# DSS_PRM register map
Vendor: Texas Instruments
Peripheral module from a debugger description file (folder TDA2Px).
Registers are 32-bit, access per field, reset 0x0 unless marked. A register's access mark holds for its fields unless they carry their own. Offsets are as the file gives them; lines under a group give offsets from that group; [hi:lo] are bit positions; {n}, {i} and the like mark numbered series; 'fields as' and 'values as' point back to an identical list; <NAME> marks a mode.

## DSS_PRM
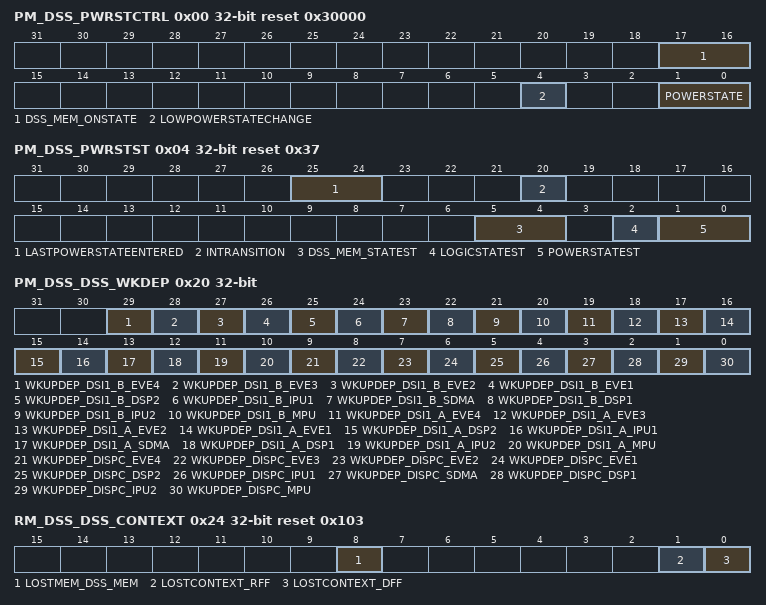
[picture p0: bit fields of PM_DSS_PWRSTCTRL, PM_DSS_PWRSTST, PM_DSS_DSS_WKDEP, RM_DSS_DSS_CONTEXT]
0x00 PM_DSS_PWRSTCTRL reset 0x30000 — This register controls the DSS power state to reach upon a domain sleep transition
  [17:16] DSS_MEM_ONSTATE ro — DSS_MEM state when domain is ON.
    3=MEM_ON (Memory bank is on when the domain is ON.)
  [4] LOWPOWERSTATECHANGE rw — Power state change request when domain has already performed a sleep transition. Allows going into deeper low power state without waking up the power domain.
    0=DIS (Do not request a low power state change.); 1=EN (Request a low power state change. This bit is automatically cleared when the power state is effectively changed or when power state is ON.)
  [1:0] POWERSTATE rw — Power state control
    0=OFF (OFF state); 1=RET (Reserved); 2=INACT (Reserved); 3=ON (ON State)
0x04 PM_DSS_PWRSTST reset 0x37 — This register provides a status on the current DSS power domain state. [warm reset insensitive]
  [25:24] LASTPOWERSTATEENTERED rw — Last low power state entered. Set to 0x3 upon write of the same only. This register is intended for debug purpose only.
    0=OFF (Power domain was previously OFF); 1=RET (Reserved); 2=INACTIVE (Reserved); 3=ON (Power domain was previously ON-ACTIVE)
  [20] INTRANSITION ro — Domain transition status
    0=NO (No on-going transition on power domain); 1=ONGOING (Power domain transition is in progress.)
  [5:4] DSS_MEM_STATEST ro — DSS_MEM state status
    0=MEM_OFF (Memory is OFF); 3=MEM_ON (Memory is ON)
  [2] LOGICSTATEST ro — Logic state status
    0=OFF (Reserved); 1=ON (Logic in domain is ON)
  [1:0] POWERSTATEST ro — Current power state status
    0=OFF (Power domain is OFF); 1=RET (Reserved); 2=INACTIVE (Reserved); 3=ON (Power domain is ON-ACTIVE)
0x20 PM_DSS_DSS_WKDEP — This register controls wakeup dependency based on DSS service requests.
  [29] WKUPDEP_DSI1_B_EVE4 rw — Wakeup dependency from DSS module (SWakeup signal) towards EVE4 + L3_MAIN1 + L4PER1 + L4PER2 + L4PER3 domainsEVE4 is not supported in this family of devices.
    0=DISABLED (Dependency is disabled); 1=ENABLED (Dependency is enabled)
  [28] WKUPDEP_DSI1_B_EVE3 rw — Wakeup dependency from DSS module (SWakeup signal) towards EVE3 + L3_MAIN1 + L4PER1 + L4PER2 + L4PER3 domainsEVE3 is not supported in this family of devices.
    values as WKUPDEP_DSI1_B_EVE4
  [27] WKUPDEP_DSI1_B_EVE2 rw — Wakeup dependency from DSS module (SWakeup signal) towards EVE2 + L3_MAIN1 + L4PER1 + L4PER2 + L4PER3 domains
    values as WKUPDEP_DSI1_B_EVE4
  [26] WKUPDEP_DSI1_B_EVE1 rw — Wakeup dependency from DSS module (SWakeup signal) towards EVE1 + L3_MAIN1 + L4PER1 + L4PER2 + L4PER3 domains
    values as WKUPDEP_DSI1_B_EVE4
  [25] WKUPDEP_DSI1_B_DSP2 rw — Wakeup dependency from DSS module (SWakeup signal) towards DSP2 + L3_MAIN1 + L4PER1 + L4PER2 + L4PER3 domains
    values as WKUPDEP_DSI1_B_EVE4
  [24] WKUPDEP_DSI1_B_IPU1 rw — Wakeup dependency from DSS module (SWakeup signal) towards IPU1 + L3_MAIN1 + L4PER1 + L4PER2 + L4PER3 domains
    values as WKUPDEP_DSI1_B_EVE4
  [23] WKUPDEP_DSI1_B_SDMA rw — Wakeup dependency from DSS module (SWakeup signal) towards SDMA + L3MAIN1 + L4PER1 + L4PER2 + L4PER3 domains
    0=Dependency_is_disabled; 1=Dependency_is_enabled
  [22] WKUPDEP_DSI1_B_DSP1 rw — Wakeup dependency from DSS module (SWakeup signal) towards DSP1 + L3_MAIN1 + L4PER1 + L4PER2 + L4PER3 domains
    values as WKUPDEP_DSI1_B_EVE4
  [21] WKUPDEP_DSI1_B_IPU2 rw — Wakeup dependency from DSS module (SWakeup signal) towards IPU2 + L3_MAIN1 + L4PER1 + L4PER2 + L4PER3 domains
    0=Dependency_is_disabled; 1=Dependency_is_enabled
  [20] WKUPDEP_DSI1_B_MPU rw — Wakeup dependency from DSS module (SWakeup signal) towards MPU + L3_MAIN1 + L4PER1 + L4PER2 + L4PER3 domains
    values as WKUPDEP_DSI1_B_EVE4
  [19] WKUPDEP_DSI1_A_EVE4 rw — Wakeup dependency from DSS module (SWakeup signal) towards EVE4 + L3_MAIN1 + L4PER1 + L4PER2 + L4PER3 domainsEVE4 is not supported in this family of devices.
    values as WKUPDEP_DSI1_B_EVE4
  [18] WKUPDEP_DSI1_A_EVE3 rw — Wakeup dependency from DSS module (SWakeup signal) towards EVE3 + L3_MAIN1 + L4PER1 + L4PER2 + L4PER3 domainsEVE3 is not supported in this family of devices.
    values as WKUPDEP_DSI1_B_EVE4
  [17] WKUPDEP_DSI1_A_EVE2 rw — Wakeup dependency from DSS module (SWakeup signal) towards EVE2 + L3_MAIN1 + L4PER1 + L4PER2 + L4PER3 domains
    values as WKUPDEP_DSI1_B_EVE4
  [16] WKUPDEP_DSI1_A_EVE1 rw — Wakeup dependency from DSS module (SWakeup signal) towards EVE1 + L3_MAIN1 + L4PER1 + L4PER2 + L4PER3 domains
    values as WKUPDEP_DSI1_B_EVE4
  [15] WKUPDEP_DSI1_A_DSP2 rw — Wakeup dependency from DSS module (SWakeup signal) towards DSP2 + L3_MAIN1 + L4PER1 + L4PER2 + L4PER3 domains
    values as WKUPDEP_DSI1_B_EVE4
  [14] WKUPDEP_DSI1_A_IPU1 rw — Wakeup dependency from DSS module (SWakeup signal) towards IPU1 + L3_MAIN1 + L4PER1 + L4PER2 + L4PER3 domains
    values as WKUPDEP_DSI1_B_EVE4
  [13] WKUPDEP_DSI1_A_SDMA rw — Wakeup dependency from DSS module (SWakeup signal) towards SDMA + L3MAIN1 + L4PER1 + L4PER2 + L4PER3 domains
    0=Dependency_is_disabled; 1=Dependency_is_enabled
  [12] WKUPDEP_DSI1_A_DSP1 rw — Wakeup dependency from DSS module (SWakeup signal) towards DSP1 + L3_MAIN1 + L4PER1 + L4PER2 + L4PER3 domains
    values as WKUPDEP_DSI1_B_EVE4
  [11] WKUPDEP_DSI1_A_IPU2 rw — Wakeup dependency from DSS module (SWakeup signal) towards IPU2 + L3_MAIN1 + L4PER1 + L4PER2 + L4PER3 domains
    0=Dependency_is_disabled; 1=Dependency_is_enabled
  [10] WKUPDEP_DSI1_A_MPU rw — Wakeup dependency from DSS module (SWakeup signal) towards MPU + L3_MAIN1 + L4PER1 + L4PER2 + L4PER3 domains
    values as WKUPDEP_DSI1_B_EVE4
  [9] WKUPDEP_DISPC_EVE4 rw — Wakeup dependency from DSS module (SWakeup signal) towards EVE4 + L3_MAIN1 + L4PER1 + L4PER2 + L4PER3 domainsEVE4 is not supported in this family of devices.
    values as WKUPDEP_DSI1_B_EVE4
  [8] WKUPDEP_DISPC_EVE3 rw — Wakeup dependency from DSS module (SWakeup signal) towards EVE3 + L3_MAIN1 + L4PER1 + L4PER2 + L4PER3 domainsEVE3 is not supported in this family of devices.
    values as WKUPDEP_DSI1_B_EVE4
  [7] WKUPDEP_DISPC_EVE2 rw — Wakeup dependency from DSS module (SWakeup signal) towards EVE2 + L3_MAIN1 + L4PER1 + L4PER2 + L4PER3 domains
    values as WKUPDEP_DSI1_B_EVE4
  [6] WKUPDEP_DISPC_EVE1 rw — Wakeup dependency from DSS module (SWakeup signal) towards EVE1 + L3_MAIN1 + L4PER1 + L4PER2 + L4PER3 domains
    values as WKUPDEP_DSI1_B_EVE4
  [5] WKUPDEP_DISPC_DSP2 rw — Wakeup dependency from DSS module (SWakeup signal) towards DSP2 + L3_MAIN1 + L4PER1 + L4PER2 + L4PER3 domains
    values as WKUPDEP_DSI1_B_EVE4
  [4] WKUPDEP_DISPC_IPU1 rw — Wakeup dependency from DSS module (SWakeup signal) towards IPU1 + L3_MAIN1 + L4PER1 + L4PER2 + L4PER3 domains
    values as WKUPDEP_DSI1_B_EVE4
  [3] WKUPDEP_DISPC_SDMA rw — Wakeup dependency from DSS module (SWakeup signal) towards SDMA + L3MAIN1 + L4PER1 + L4PER2 + L4PER3 domains
    0=Dependency_is_disabled; 1=Dependency_is_enabled
  [2] WKUPDEP_DISPC_DSP1 rw — Wakeup dependency from DSS module (SWakeup signal) towards DSP1 + L3_MAIN1 + L4PER1 + L4PER2 + L4PER3 domains
    values as WKUPDEP_DSI1_B_EVE4
  [1] WKUPDEP_DISPC_IPU2 rw — Wakeup dependency from DSS module (SWakeup signal) towards IPU2 + L3_MAIN1 + L4PER1 + L4PER2 + L4PER3 domains
    0=Dependency_is_disabled; 1=Dependency_is_enabled
  [0] WKUPDEP_DISPC_MPU rw — Wakeup dependency from DSS module (SWakeup signal) towards MPU + L3_MAIN1 + L4PER1 + L4PER2 + L4PER3 domains
    values as WKUPDEP_DSI1_B_EVE4
0x24 RM_DSS_DSS_CONTEXT reset 0x103 — This register contains dedicated DSS context statuses. [warm reset insensitive]
  [all] fields
    0=MAINTAINED (Context has been maintained); 1=LOST (Context has been lost)
  [8] LOSTMEM_DSS_MEM rw — Specify if memory-based context in DSS_MEM memory bank has been lost due to a previous power transition or other reset source.
  [1] LOSTCONTEXT_RFF rw — Specify if RFF-based context has been lost due to a previous power transition or other reset source. (set upon assertion of DSS_RET_RST signal)
  [0] LOSTCONTEXT_DFF rw — Specify if DFF-based context has been lost due to a previous power transition or other reset source. (set upon assertion of DSS_RST signal)
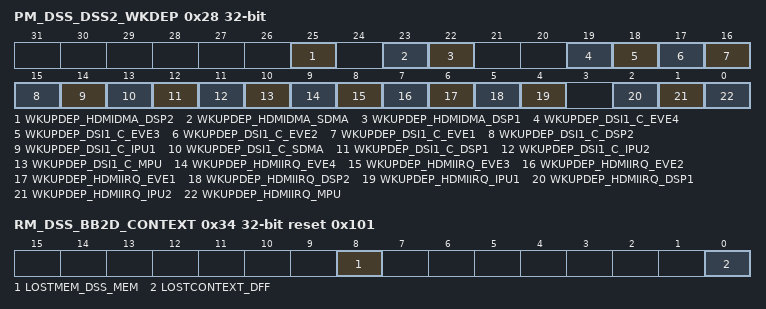
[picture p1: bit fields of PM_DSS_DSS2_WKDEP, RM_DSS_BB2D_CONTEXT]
0x28 PM_DSS_DSS2_WKDEP — This register controls wakeup dependency based on DSS service requests.
  [25] WKUPDEP_HDMIDMA_DSP2 rw — Wakeup dependency from DSS module (SWakeup signal) towards DSP2 + L3_MAIN1 + L4PER1 + L4PER2 + L4PER3 domains
    values as PM_DSS_DSS_WKDEP.WKUPDEP_DSI1_B_EVE4
  [23] WKUPDEP_HDMIDMA_SDMA rw — Wakeup dependency from DSS module (SWakeup signal) towards SDMA + L3MAIN1 + L4PER1 + L4PER2 + L4PER3 domains
    0=Dependency_is_disabled; 1=Dependency_is_enabled
  [22] WKUPDEP_HDMIDMA_DSP1 rw — Wakeup dependency from DSS module (SWakeup signal) towards DSP1 + L3_MAIN1 + L4PER1 + L4PER2 + L4PER3 domains
    values as PM_DSS_DSS_WKDEP.WKUPDEP_DSI1_B_EVE4
  [19] WKUPDEP_DSI1_C_EVE4 rw — Wakeup dependency from DSS module (SWakeup signal) towards EVE4 + L3_MAIN1 + L4PER1 + L4PER2 + L4PER3 domainsEVE4 is not supported in this family of devices.
    values as PM_DSS_DSS_WKDEP.WKUPDEP_DSI1_B_EVE4
  [18] WKUPDEP_DSI1_C_EVE3 rw — Wakeup dependency from DSS module (SWakeup signal) towards EVE3 + L3_MAIN1 + L4PER1 + L4PER2 + L4PER3 domainsEVE3 is not supported in this family of devices.
    values as PM_DSS_DSS_WKDEP.WKUPDEP_DSI1_B_EVE4
  [17] WKUPDEP_DSI1_C_EVE2 rw — Wakeup dependency from DSS module (SWakeup signal) towards EVE2 + L3_MAIN1 + L4PER1 + L4PER2 + L4PER3 domains
    values as PM_DSS_DSS_WKDEP.WKUPDEP_DSI1_B_EVE4
  [16] WKUPDEP_DSI1_C_EVE1 rw — Wakeup dependency from DSS module (SWakeup signal) towards EVE1 + L3_MAIN1 + L4PER1 + L4PER2 + L4PER3 domains
    values as PM_DSS_DSS_WKDEP.WKUPDEP_DSI1_B_EVE4
  [15] WKUPDEP_DSI1_C_DSP2 rw — Wakeup dependency from DSS module (SWakeup signal) towards DSP2 + L3_MAIN1 + L4PER1 + L4PER2 + L4PER3 domains
    values as PM_DSS_DSS_WKDEP.WKUPDEP_DSI1_B_EVE4
  [14] WKUPDEP_DSI1_C_IPU1 rw — Wakeup dependency from DSS module (SWakeup signal) towards IPU1 + L3_MAIN1 + L4PER1 + L4PER2 + L4PER3 domains
    values as PM_DSS_DSS_WKDEP.WKUPDEP_DSI1_B_EVE4
  [13] WKUPDEP_DSI1_C_SDMA rw — Wakeup dependency from DSS module (SWakeup signal) towards SDMA + L3MAIN1 + L4PER1 + L4PER2 + L4PER3 domains
    0=Dependency_is_disabled; 1=Dependency_is_enabled
  [12] WKUPDEP_DSI1_C_DSP1 rw — Wakeup dependency from DSS module (SWakeup signal) towards DSP1 + L3_MAIN1 + L4PER1 + L4PER2 + L4PER3 domains
    values as PM_DSS_DSS_WKDEP.WKUPDEP_DSI1_B_EVE4
  [11] WKUPDEP_DSI1_C_IPU2 rw — Wakeup dependency from DSS module (SWakeup signal) towards IPU2 + L3_MAIN1 + L4PER1 + L4PER2 + L4PER3 domains
    0=Dependency_is_disabled; 1=Dependency_is_enabled
  [10] WKUPDEP_DSI1_C_MPU rw — Wakeup dependency from DSS module (SWakeup signal) towards MPU + L3_MAIN1 + L4PER1 + L4PER2 + L4PER3 domains
    values as PM_DSS_DSS_WKDEP.WKUPDEP_DSI1_B_EVE4
  [9] WKUPDEP_HDMIIRQ_EVE4 rw — Wakeup dependency from DSS module (SWakeup signal) towards EVE4 + L3_MAIN1 + L4PER1 + L4PER2 + L4PER3 domainsEVE4 is not supported in this family of devices.
    values as PM_DSS_DSS_WKDEP.WKUPDEP_DSI1_B_EVE4
  [8] WKUPDEP_HDMIIRQ_EVE3 rw — Wakeup dependency from DSS module (SWakeup signal) towards EVE3 + L3_MAIN1 + L4PER1 + L4PER2 + L4PER3 domainsEVE3 is not supported in this family of devices.
    values as PM_DSS_DSS_WKDEP.WKUPDEP_DSI1_B_EVE4
  [7] WKUPDEP_HDMIIRQ_EVE2 rw — Wakeup dependency from DSS module (SWakeup signal) towards EVE2 + L3_MAIN1 + L4PER1 + L4PER2 + L4PER3 domains
    values as PM_DSS_DSS_WKDEP.WKUPDEP_DSI1_B_EVE4
  [6] WKUPDEP_HDMIIRQ_EVE1 rw — Wakeup dependency from DSS module (SWakeup signal) towards EVE1 + L3_MAIN1 + L4PER1 + L4PER2 + L4PER3 domains
    values as PM_DSS_DSS_WKDEP.WKUPDEP_DSI1_B_EVE4
  [5] WKUPDEP_HDMIIRQ_DSP2 rw — Wakeup dependency from DSS module (SWakeup signal) towards DSP2 + L3_MAIN1 + L4PER1 + L4PER2 + L4PER3 domains
    values as PM_DSS_DSS_WKDEP.WKUPDEP_DSI1_B_EVE4
  [4] WKUPDEP_HDMIIRQ_IPU1 rw — Wakeup dependency from DSS module (SWakeup signal) towards IPU1 + L3_MAIN1 + L4PER1 + L4PER2 + L4PER3 domains
    values as PM_DSS_DSS_WKDEP.WKUPDEP_DSI1_B_EVE4
  [2] WKUPDEP_HDMIIRQ_DSP1 rw — Wakeup dependency from DSS module (SWakeup signal) towards DSP1 + L3_MAIN1 + L4PER1 + L4PER2 + L4PER3 domains
    values as PM_DSS_DSS_WKDEP.WKUPDEP_DSI1_B_EVE4
  [1] WKUPDEP_HDMIIRQ_IPU2 rw — Wakeup dependency from DSS module (SWakeup signal) towards IPU2 + L3_MAIN1 + L4PER1 + L4PER2 + L4PER3 domains
    0=Dependency_is_disabled; 1=Dependency_is_enabled
  [0] WKUPDEP_HDMIIRQ_MPU rw — Wakeup dependency from DSS module (SWakeup signal) towards MPU + L3_MAIN1 + L4PER1 + L4PER2 + L4PER3 domains
    values as PM_DSS_DSS_WKDEP.WKUPDEP_DSI1_B_EVE4
0x34 RM_DSS_BB2D_CONTEXT reset 0x101 — This register contains dedicated BB2B context statuses. [warm reset insensitive]
  [8] LOSTMEM_DSS_MEM rw — Specify if memory-based context in DSS_MEM memory bank has been lost due to a previous power transition or other reset source.
    values as the fields of RM_DSS_DSS_CONTEXT
  [0] LOSTCONTEXT_DFF rw — Specify if DFF-based context has been lost due to a previous power transition or other reset source. (set upon assertion of DSS_RST signal)
    values as the fields of RM_DSS_DSS_CONTEXT
